# vpac_targetdb register map
Vendor: Texas Instruments
Registers are 32-bit, read-write, no defined reset value unless marked. A register's access mark holds for its fields unless they carry their own. Offsets are as the file gives them; [hi:lo] are bit positions; {n}, {i} and the like mark numbered series; 'fields as' and 'values as' point back to an identical list.

## VPAC (part 4 of 8) — Vision Pre-Processing Accelerator (VPAC)
0x100 GLBCECONFIG — GLBCE Configuration
  [0] GLBCE_PCLKFREE — '1'-> GLBCE pclk is free running , '0' -> GLBCE pclk is gated pixel clock
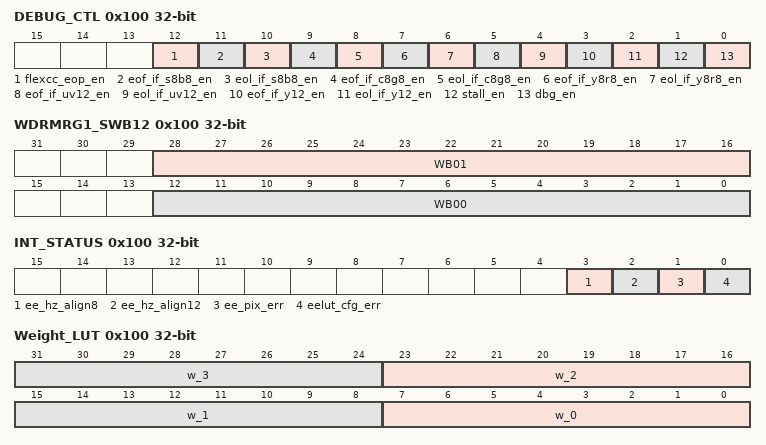
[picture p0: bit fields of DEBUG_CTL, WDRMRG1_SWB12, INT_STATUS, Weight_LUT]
0x100 DEBUG_CTL access per field — Enable for different debug events
  [12] flexcc_eop_en rw — Enable for flexcc eop
  [11] eof_if_s8b8_en rw — Enable for eof on s8b8
  [10] eol_if_s8b8_en rw — Enable for eol on s8b8
  [9] eof_if_c8g8_en rw — Enable for eof on c8g8
  [8] eol_if_c8g8_en rw — Enable for eol on c8g8
  [7] eof_if_y8r8_en rw — Enable for eof on y8r8
  [6] eol_if_y8r8_en rw — Enable for eol on y8r8
  [5] eof_if_uv12_en rw — Enable for eof on uv12
  [4] eol_if_uv12_en rw — Enable for eol on uv12
  [3] eof_if_y12_en rw — Enable for eof on y12
  [2] eol_if_y12_en rw — Enable for eol on y12
  [1] stall_en rw — Enable for stall event
  [0] dbg_en rw — Enable debug features, set to '0' to disable all debug events
0x100 WDRMRG1_SWB12 access per field — First stage WDR merge WB gain 1 and 2 for short frame
  [28:16] WB01 rw — U13Q9, WB gain for short frame at pixel 01
  [12:0] WB00 rw — U13Q9, WB gain for short frame at pixel 00
0x100 INT_STATUS — Status/clear register for flexee interrupts
  [3] ee_hz_align8 — status/clear for EE horizontal aligner yuv8 overflow error indicates that the luma and chroma line starts were not within hardware synchronization limits. Write 1 to clear, write 0 has no effect.
  [2] ee_hz_align12 — status/clear for EE horizontal aligner yuv12 overflow error indicates that the luma and chroma line starts were not within hardware synchronization limits. Write 1 to clear, write 0 has no effect.
  [1] ee_pix_err — status/clear for error on line array, set when software accesses EE pixel array during active frame causing potential frame corruption. Write 1 to clear, write 0 has no effect.
  [0] eelut_cfg_err — status/clear for error on EE LUT cfg, set when software accesses EE LUT during active frame causing potential frame corruption. Write 1 to clear, write 0 has no effect.
0x100 Weight_LUT — This contains weights for LUT. These acts as 1280 size LUT (8 bit each) in Bi-lateral mode, while 24 size (9 bit in 16 bit container) in Generic Filtering mode
  [8n+7:8n] w_{n} (n=0..3) — weight W_{n}
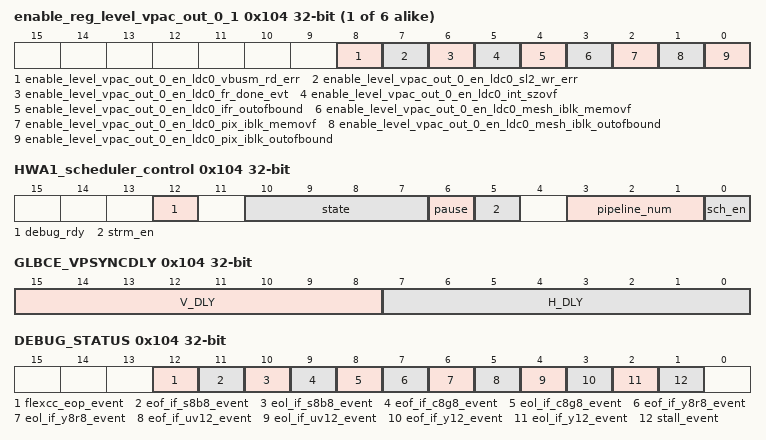
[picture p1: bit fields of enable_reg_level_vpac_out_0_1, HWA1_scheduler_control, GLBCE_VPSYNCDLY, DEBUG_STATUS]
{0x104+0x20*i} enable_reg_level_vpac_out_{i}_1 (i=0..5) — Enable Register {8i+1}
  [8] enable_level_vpac_out_{i}_en_ldc0_vbusm_rd_err — Enable Set for level_vpac_out_{i}_en_ldc0_vbusm_rd_err
  [7] enable_level_vpac_out_{i}_en_ldc0_sl2_wr_err — Enable Set for level_vpac_out_{i}_en_ldc0_sl2_wr_err
  [6] enable_level_vpac_out_{i}_en_ldc0_fr_done_evt — Enable Set for level_vpac_out_{i}_en_ldc0_fr_done_evt
  [5] enable_level_vpac_out_{i}_en_ldc0_int_szovf — Enable Set for level_vpac_out_{i}_en_ldc0_int_szovf
  [4] enable_level_vpac_out_{i}_en_ldc0_ifr_outofbound — Enable Set for level_vpac_out_{i}_en_ldc0_ifr_outofbound
  [3] enable_level_vpac_out_{i}_en_ldc0_mesh_iblk_memovf — Enable Set for level_vpac_out_{i}_en_ldc0_mesh_iblk_memovf
  [2] enable_level_vpac_out_{i}_en_ldc0_pix_iblk_memovf — Enable Set for level_vpac_out_{i}_en_ldc0_pix_iblk_memovf
  [1] enable_level_vpac_out_{i}_en_ldc0_mesh_iblk_outofbound — Enable Set for level_vpac_out_{i}_en_ldc0_mesh_iblk_outofbound
  [0] enable_level_vpac_out_{i}_en_ldc0_pix_iblk_outofbound — Enable Set for level_vpac_out_{i}_en_ldc0_pix_iblk_outofbound
0x104 HWA1_scheduler_control access per field — Scheduler Control Register
  [12] debug_rdy rw — '0' -> HWA1 Scheduler resources must not be read during halted state. '1'-> HWA1 Scheduler resources are readable during halted state
  [10:7] state ro — Current state of HWA1 Scheduler
  [6] pause rw — '1' -> pause/suspend scheduler , '0' -> resume scheduler
  [5] strm_en rw — '1' -> Streaming input enable, '0' No streaming input
  [3:1] pipeline_num rw — Pipeline Number of HWA1 Scheduler
  [0] sch_en rw — scheduler enable; write '1' to enable scheduler
0x104 GLBCE_VPSYNCDLY — Delay of GLBCE Core, used to regenerate VS/VE VPORT signals
  [15:8] V_DLY — Line delay between GLBCE.VS_In to GLBCE.VS_Out
  [7:0] H_DLY — Cycle delay between GLBCE.HS_In to GLBCE.HS_Out minus 1
0x104 DEBUG_STATUS access per field — Set/Clear for debug events
  [12] flexcc_eop_event rw — Status/Clear for flexcc eop, write '1' to clear
  [11] eof_if_s8b8_event rw — Status/Clear for eof on s8b8, write '1' to clear
  [10] eol_if_s8b8_event rw — Status/Clear for eol on s8b8, write '1' to clear
  [9] eof_if_c8g8_event rw — Status/Clear for eof on c8g8, write '1' to clear
  [8] eol_if_c8g8_event rw — Status/Clear for eol on c8g8, write '1' to clear
  [7] eof_if_y8r8_event rw — Status/Clear for eof on y8r8, write '1' to clear
  [6] eol_if_y8r8_event rw — Status/Clear for eol on y8r8, write '1' to clear
  [5] eof_if_uv12_event rw — Status/Clear for eof on uv12, write '1' to clear
  [4] eol_if_uv12_event rw — Status/Clear for eol on uv12, write '1' to clear
  [3] eof_if_y12_event rw — Status/Clear for eof on y12, write '1' to clear
  [2] eol_if_y12_event rw — Status/Clear for eol on y12, write '1' to clear
  [1] stall_event rw — Status/Clear for stall event, write '1' to clear
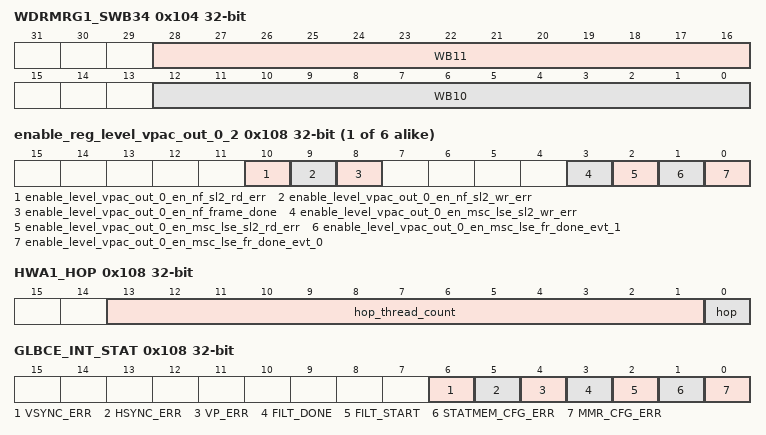
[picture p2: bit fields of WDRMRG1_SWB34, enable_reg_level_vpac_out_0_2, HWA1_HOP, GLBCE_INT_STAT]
0x104 WDRMRG1_SWB34 access per field — First stage WDR merge WB gain 3 and 4 for short frame
  [28:16] WB11 rw — U13Q9, WB gain for short frame at pixel 11
  [12:0] WB10 rw — U13Q9, WB gain for short frame at pixel 10
{0x108+0x20*i} enable_reg_level_vpac_out_{i}_2 (i=0..5) — Enable Register {8i+2}
  [10] enable_level_vpac_out_{i}_en_nf_sl2_rd_err — Enable Set for level_vpac_out_{i}_en_nf_sl2_rd_err
  [9] enable_level_vpac_out_{i}_en_nf_sl2_wr_err — Enable Set for level_vpac_out_{i}_en_nf_sl2_wr_err
  [8] enable_level_vpac_out_{i}_en_nf_frame_done — Enable Set for level_vpac_out_{i}_en_nf_frame_done
  [3] enable_level_vpac_out_{i}_en_msc_lse_sl2_wr_err — Enable Set for level_vpac_out_{i}_en_msc_lse_sl2_wr_err
  [2] enable_level_vpac_out_{i}_en_msc_lse_sl2_rd_err — Enable Set for level_vpac_out_{i}_en_msc_lse_sl2_rd_err
  [1] enable_level_vpac_out_{i}_en_msc_lse_fr_done_evt_1 — Enable Set for level_vpac_out_{i}_en_msc_lse_fr_done_evt_1
  [0] enable_level_vpac_out_{i}_en_msc_lse_fr_done_evt_0 — Enable Set for level_vpac_out_{i}_en_msc_lse_fr_done_evt_0
0x108 HWA1_HOP — Scheduler HOP Control Register. Help in detecting eop within scheduler. Once configured, it counts task/channel starts and stops issuing further start. Specifically useful for Head of pipe dma scheduler .
  [13:1] hop_thread_count — Number of Task count for Head of pipe
  [0] hop — '1' -> Head of Pipe producer Sch , '0' -> No hop
0x108 GLBCE_INT_STAT — Set on internal interutp event and clr by SW
  [6] VSYNC_ERR — status/clear for GLBCE VSYNC Delay programmation error. Set Delayed sync signals doesn't match with sync signal generated from GLBCE Core
  [5] HSYNC_ERR — status/clear for GLBCE HSYNC Delay programmation error. Set Delayed sync signals doesn't match with sync signal generated from GLBCE Core
  [4] VP_ERR — status/clear for GLBCE Input frame start error. Set Input frame is started while filtering is going on
  [3] FILT_DONE — status/clear for GLBCE Filtering Done event. Set when GLBCE Filtering is completed.
  [2] FILT_START — status/clear for GLBCE Filtering Start event. Set when GLBCE Filtering starts
  [1] STATMEM_CFG_ERR — status/clear for statastics memory configuration error. Set when access happen to statastics memory in the middle of processing
  [0] MMR_CFG_ERR — status/clear for mmr configuration error. Set when writes happen to non-shadowed registers in the middle of processing
0x108 DEBUG_RAW — Set/Clear for debug RAW mode
  [0] dbg_raw_mode — Enable debug RAW mode, takes input from RAWFE and delivers to FlexCC as C1={raw[11:0]}, C2={4'd0,raw[7:0]}, C3={4'd0,raw[15:8]}, c4={8'd0,raw[15:12]}
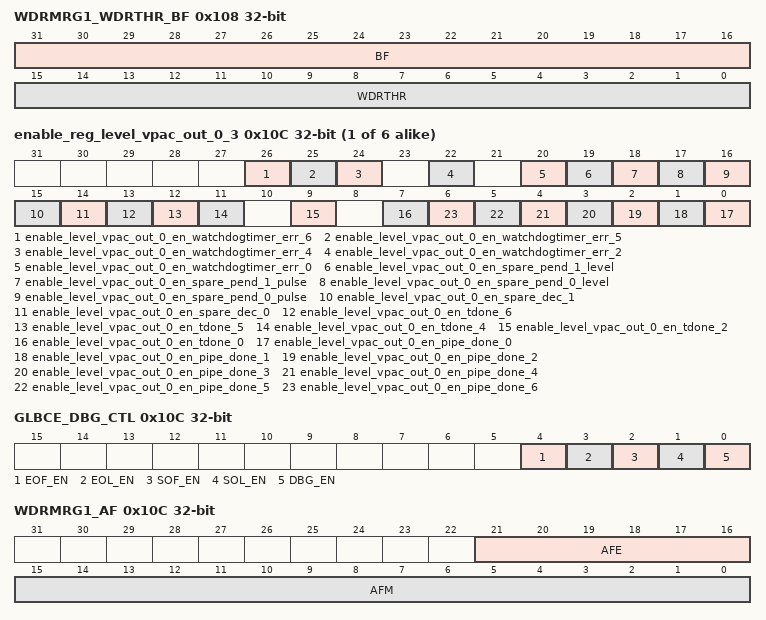
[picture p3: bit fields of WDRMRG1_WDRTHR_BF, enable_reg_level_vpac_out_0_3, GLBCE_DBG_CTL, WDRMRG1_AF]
0x108 WDRMRG1_WDRTHR_BF — First stage WDR merge parameter WDRTHR and BF
  [31:16] BF — S16, bf parameter for merge
  [15:0] WDRTHR — U16, WDR threshold for merge
{0x10C+0x20*i} enable_reg_level_vpac_out_{i}_3 (i=0..5) — Enable Register {8i+3}
  [26] enable_level_vpac_out_{i}_en_watchdogtimer_err_6 — Enable Set for level_vpac_out_{i}_en_watchdogtimer_err_6
  [25] enable_level_vpac_out_{i}_en_watchdogtimer_err_5 — Enable Set for level_vpac_out_{i}_en_watchdogtimer_err_5
  [24] enable_level_vpac_out_{i}_en_watchdogtimer_err_4 — Enable Set for level_vpac_out_{i}_en_watchdogtimer_err_4
  [22] enable_level_vpac_out_{i}_en_watchdogtimer_err_2 — Enable Set for level_vpac_out_{i}_en_watchdogtimer_err_2
  [20] enable_level_vpac_out_{i}_en_watchdogtimer_err_0 — Enable Set for level_vpac_out_{i}_en_watchdogtimer_err_0
  [19] enable_level_vpac_out_{i}_en_spare_pend_1_level — Enable Set for level_vpac_out_{i}_en_spare_pend_1_level
  [18] enable_level_vpac_out_{i}_en_spare_pend_1_pulse — Enable Set for level_vpac_out_{i}_en_spare_pend_1_pulse
  [17] enable_level_vpac_out_{i}_en_spare_pend_0_level — Enable Set for level_vpac_out_{i}_en_spare_pend_0_level
  [16] enable_level_vpac_out_{i}_en_spare_pend_0_pulse — Enable Set for level_vpac_out_{i}_en_spare_pend_0_pulse
  [15] enable_level_vpac_out_{i}_en_spare_dec_1 — Enable Set for level_vpac_out_{i}_en_spare_dec_1
  [14] enable_level_vpac_out_{i}_en_spare_dec_0 — Enable Set for level_vpac_out_{i}_en_spare_dec_0
  [13] enable_level_vpac_out_{i}_en_tdone_6 — Enable Set for level_vpac_out_{i}_en_tdone_6
  [12] enable_level_vpac_out_{i}_en_tdone_5 — Enable Set for level_vpac_out_{i}_en_tdone_5
  [11] enable_level_vpac_out_{i}_en_tdone_4 — Enable Set for level_vpac_out_{i}_en_tdone_4
  [9] enable_level_vpac_out_{i}_en_tdone_2 — Enable Set for level_vpac_out_{i}_en_tdone_2
  [7] enable_level_vpac_out_{i}_en_tdone_0 — Enable Set for level_vpac_out_{i}_en_tdone_0
  [n] enable_level_vpac_out_{i}_en_pipe_done_{n} (n=0..6) — Enable Set for level_vpac_out_{i}_en_pipe_done_{n}
0x10C GLBCE_DBG_CTL — Enable for GLBCE debug events
  [4] EOF_EN — Enable for EOF at GLBCE output
  [3] EOL_EN — Enable for EOF at GLBCE output
  [2] SOF_EN — Enable for SOF at GLBCE input
  [1] SOL_EN — Enable for SOL at GLBCE input
  [0] DBG_EN — Enable debug features, set to '0' to disable all debug events
0x10C WDRMRG1_AF access per field — First stage WDR merge parameter AF
  [21:16] AFE rw — U6, af_e parameter for merge
  [15:0] AFM rw — S16, af_m parameter for merge
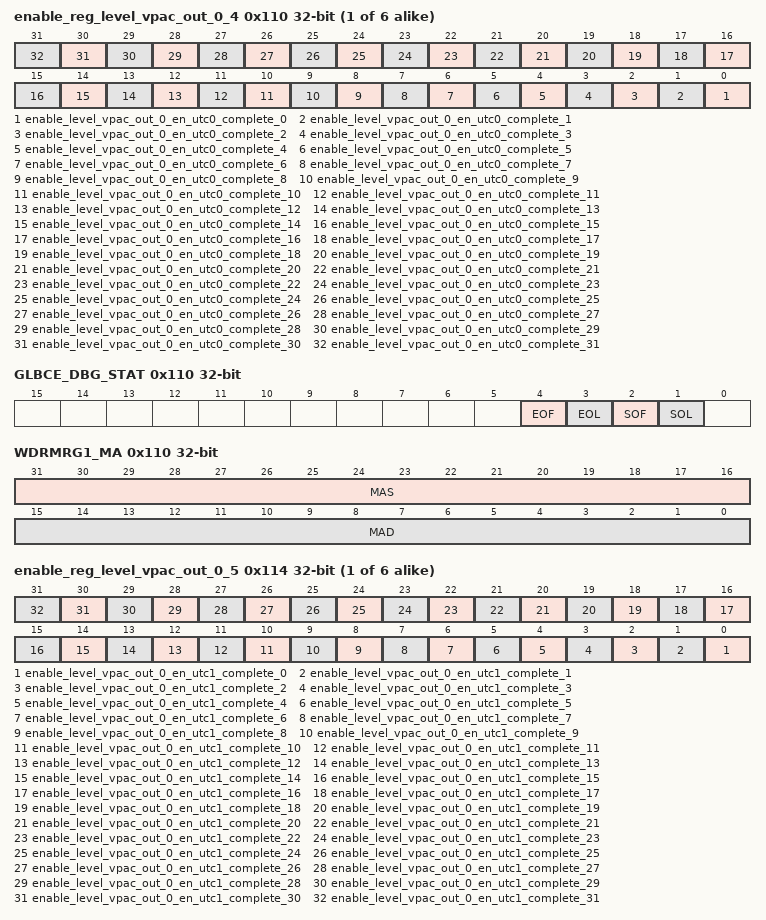
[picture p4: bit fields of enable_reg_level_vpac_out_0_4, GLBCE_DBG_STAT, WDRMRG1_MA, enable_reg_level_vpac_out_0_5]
{0x110+0x20*i} enable_reg_level_vpac_out_{i}_4 (i=0..5) — Enable Register {8i+4}
  [n] enable_level_vpac_out_{i}_en_utc0_complete_{n} (n=0..31) — Enable Set for level_vpac_out_{i}_en_utc0_complete_{n}
0x110 GLBCE_DBG_STAT — Set/Clear for GLBCE debug events
  [4] EOF — Status/Clear for EOF at GLBCE output. Set on EOF at GLBCE output
  [3] EOL — Status/Clear for EOF at GLBCE output. Set on EOL at GLBCE output
  [2] SOF — Status/Clear for SOF at GLBCE input. Set on SOF at GLBCE input
  [1] SOL — Status/Clear for SOL at GLBCE input. Set on SOL at GLBCE input
0x110 WDRMRG1_MA — First stage WDR merge parameter MA
  [31:16] MAS — U16, slope for merge MA filter
  [15:0] MAD — U16, lower threshold for merge MA filter
{0x114+0x20*i} enable_reg_level_vpac_out_{i}_5 (i=0..5) — Enable Register {8i+5}
  [n] enable_level_vpac_out_{i}_en_utc1_complete_{n} (n=0..31) — Enable Set for level_vpac_out_{i}_en_utc1_complete_{n}
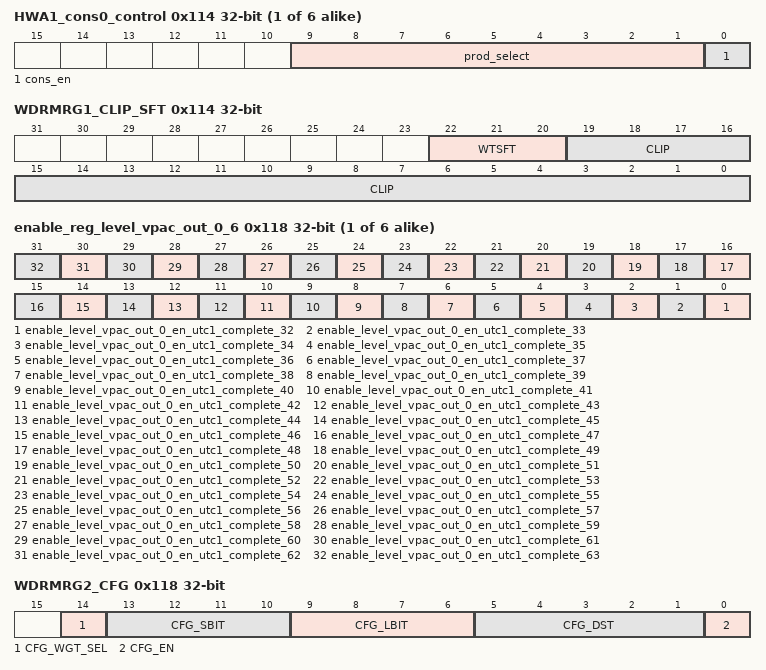
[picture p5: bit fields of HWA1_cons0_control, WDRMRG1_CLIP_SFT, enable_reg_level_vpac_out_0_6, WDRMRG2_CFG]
{0x114+4i} HWA1_cons{i}_control (i=0..5) — Controlling consumer socket {i} for HWA1
  [9:1] prod_select — producer select for HWA1 cons socket {i}
  [0] cons_en — '1' -> Consumer socket {i} enable , '0' Disable
0x114 WDRMRG1_CLIP_SFT access per field — First stage WDR merge clip value and shift before weight block
  [22:20] WTSFT rw — U3, shift before weight block
  [19:0] CLIP rw — U20, output clip value. It is a software restriction to always ensure that the clipped value is a 16-bit number for first wdr stage.
{0x118+0x20*i} enable_reg_level_vpac_out_{i}_6 (i=0..5) — Enable Register {8i+6}
  [n-32] enable_level_vpac_out_{i}_en_utc1_complete_{n} (n=32..63) — Enable Set for level_vpac_out_{i}_en_utc1_complete_{n}
0x118 WDRMRG2_CFG access per field — Second stage WDR merge configuration
  [14] CFG_WGT_SEL rw — Select source for weight calculation (0:long, 1: short)
  [13:10] CFG_SBIT rw — U4, short exposure image bit shift
  [9:6] CFG_LBIT rw — U4, long exposure image bit shift
  [5:1] CFG_DST rw — U5, down shift value after WDR merge
  [0] CFG_EN rw — enable
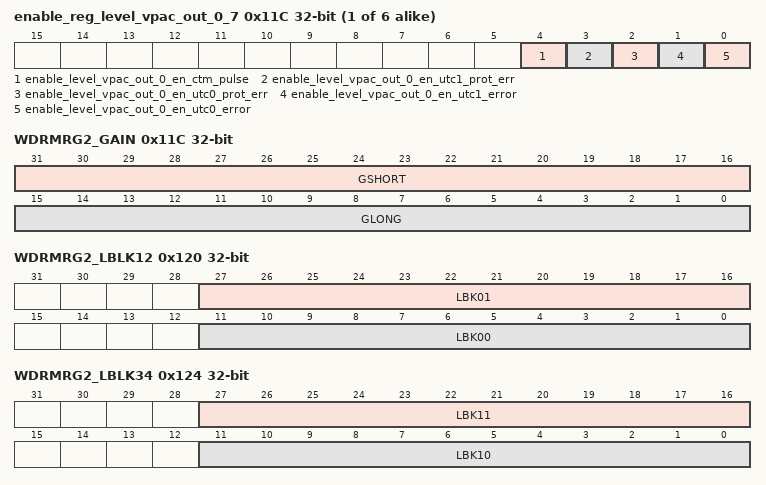
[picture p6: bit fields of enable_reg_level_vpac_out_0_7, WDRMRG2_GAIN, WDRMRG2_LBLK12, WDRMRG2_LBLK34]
{0x11C+0x20*i} enable_reg_level_vpac_out_{i}_7 (i=0..5) — Enable Register {8i+7}
  [4] enable_level_vpac_out_{i}_en_ctm_pulse — Enable Set for level_vpac_out_{i}_en_ctm_pulse
  [3] enable_level_vpac_out_{i}_en_utc1_prot_err — Enable Set for level_vpac_out_{i}_en_utc1_prot_err
  [2] enable_level_vpac_out_{i}_en_utc0_prot_err — Enable Set for level_vpac_out_{i}_en_utc0_prot_err
  [1] enable_level_vpac_out_{i}_en_utc1_error — Enable Set for level_vpac_out_{i}_en_utc1_error
  [0] enable_level_vpac_out_{i}_en_utc0_error — Enable Set for level_vpac_out_{i}_en_utc0_error
0x11C WDRMRG2_GAIN — Second stage WDR merge gain
  [31:16] GSHORT — U16Q15, gain for long frame
  [15:0] GLONG — U16Q15, gain for short frame
0x120 WDRMRG2_LBLK12 access per field — Second stage WDR merge black level 1 and 2 for long frame
  [27:16] LBK01 rw — U12, black level for long frame at pixel 01
  [11:0] LBK00 rw — U12, black level for long frame at pixel 00
0x124 WDRMRG2_LBLK34 access per field — Second stage WDR merge black level 3 and 4 for long frame
  [27:16] LBK11 rw — U12, black level for long frame at pixel 11
  [11:0] LBK10 rw — U12, black level for long frame at pixel 10
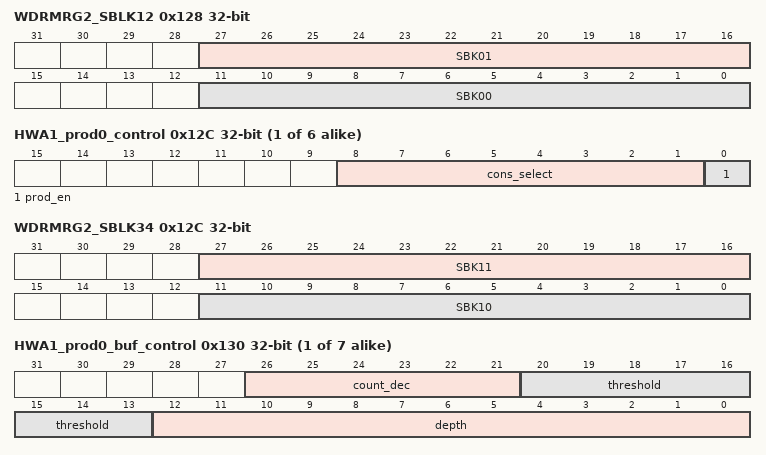
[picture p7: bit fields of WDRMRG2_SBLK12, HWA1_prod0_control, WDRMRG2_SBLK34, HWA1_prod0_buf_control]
0x128 WDRMRG2_SBLK12 access per field — Second stage WDR merge black level 1 and 2 for short frame
  [27:16] SBK01 rw — U12, black level for short frame at pixel 01
  [11:0] SBK00 rw — U12, black level for short frame at pixel 00
{0x12C+0x14*i} HWA1_prod{i}_control (i=0..5) — Controlling producer socket{i} for HWA1
  [8:1] cons_select — consumer select for HWA1 prod socket {i}. Used in decrementing count of producer buffer
  [0] prod_en — '1' -> Producer socket 0 enable , '0' Disable
0x12C WDRMRG2_SBLK34 access per field — Second stage WDR merge black level 3 and 4 for short frame
  [27:16] SBK11 rw — U12, black level for short frame at pixel 11
  [11:0] SBK10 rw — U12, black level for short frame at pixel 10
{0x130+0x14*i} HWA1_prod{i}_buf_control (i=0..6) — Controlling producer socket{i} buffer for HWA1
  [26:21] count_dec — Count decrement value for prod count
  [20:13] threshold — Count threshold to generate pend for consumer
  [12:0] depth — Maximum number of producer buffer count
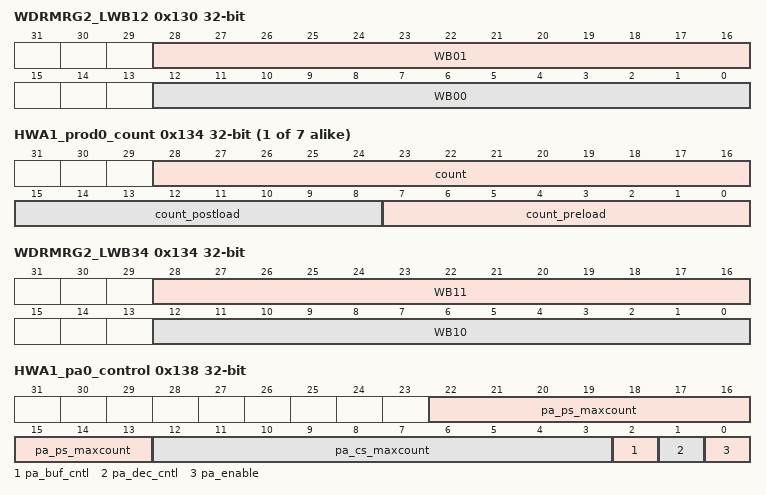
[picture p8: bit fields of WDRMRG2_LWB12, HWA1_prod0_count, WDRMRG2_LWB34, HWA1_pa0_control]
0x130 WDRMRG2_LWB12 access per field — Second stage WDR merge WB gain 1 and 2 for long frame
  [28:16] WB01 rw — U13Q9, WB gain for long frame at pixel 01
  [12:0] WB00 rw — U13Q9, WB gain for long frame at pixel 00
{0x134+0x14*i} HWA1_prod{i}_count access per field (i=0..6) — Defining count values for pre/post load for generating pend by HWA1 prod{i}
  [28:16] count ro — current count value
  [15:8] count_postload rw — count postload after producer max thread count reached
  [7:0] count_preload rw — count preload after scheduler start/init
0x134 WDRMRG2_LWB34 access per field — Second stage WDR merge WB gain 3 and 4 for long frame
  [28:16] WB11 rw — U13Q9, WB gain for long frame at pixel 11
  [12:0] WB10 rw — U13Q9, WB gain for long frame at pixel 10
0x138 HWA1_pa0_control — control register to manage pattern adapter on HWA1 prod socket0
  [22:13] pa_ps_maxcount — destination count for pattern adaptation (N), M --> N
  [12:3] pa_cs_maxcount — source count for pattern adaptation (M), M --> N
  [2] pa_buf_cntl — '1' -> Apply threshold, count_preload and count_postload on pattern adapter count (use this only when pa_enable='1') '0' -> Apply threshold, count_preload and count_postload on prod count (same behavior as if no pattern adapter. Note when pa_enable='1' and pa_buf_cntl='0' threshold is not used and ignored)
  [1] pa_dec_cntl — '1' -> post pattern adaptation, decrement ps count by count_dec , '0' -> post pattern adaptation, decrement ps count by pa_cs_maxcount
  [0] pa_enable — '1' -> pa enable, '0' -> disable
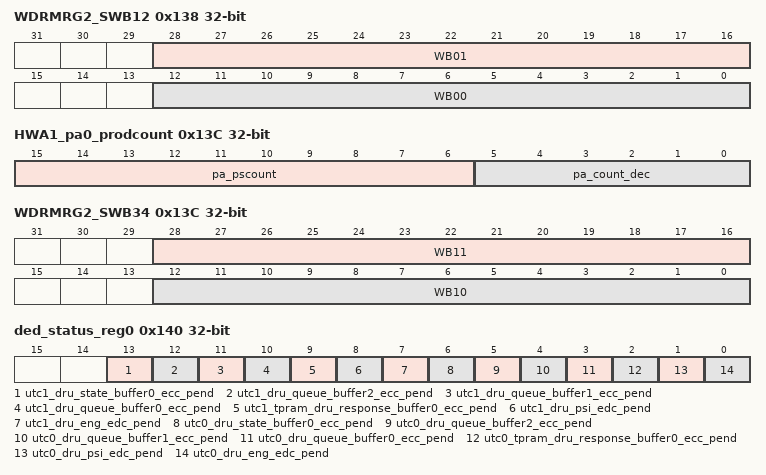
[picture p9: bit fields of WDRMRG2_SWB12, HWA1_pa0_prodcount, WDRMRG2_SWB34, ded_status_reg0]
0x138 WDRMRG2_SWB12 access per field — Second stage WDR merge WB gain 1 and 2 for short frame
  fields as WDRMRG1_SWB12
0x13C HWA1_pa0_prodcount access per field — count values for HWA1 prod socket0
  [15:6] pa_pscount ro — current count value of pa prod count
  [5:0] pa_count_dec rw — Decrement count value of pa_prod_count after pattern adapter prod count reaches threshold
0x13C ded_eoi_reg — EOI Register
  [0] eoi_wr
0x13C ded_eoi_reg — EOI Register
  [0] eoi_wr
0x13C ded_eoi_reg — EOI Register
  [0] eoi_wr
0x13C WDRMRG2_SWB34 access per field — Second stage WDR merge WB gain 3 and 4 for short frame
  fields as WDRMRG1_SWB34
0x140 ded_status_reg0 — Interrupt Status Register 0
  [13] utc1_dru_state_buffer0_ecc_pend — Interrupt Pending Status for utc1_dru_state_buffer0_ecc_pend
  [12] utc1_dru_queue_buffer2_ecc_pend — Interrupt Pending Status for utc1_dru_queue_buffer2_ecc_pend
  [11] utc1_dru_queue_buffer1_ecc_pend — Interrupt Pending Status for utc1_dru_queue_buffer1_ecc_pend
  [10] utc1_dru_queue_buffer0_ecc_pend — Interrupt Pending Status for utc1_dru_queue_buffer0_ecc_pend
  [9] utc1_tpram_dru_response_buffer0_ecc_pend — Interrupt Pending Status for utc1_tpram_dru_response_buffer0_ecc_pend
  [8] utc1_dru_psi_edc_pend — Interrupt Pending Status for utc1_dru_psi_edc_pend
  [7] utc1_dru_eng_edc_pend — Interrupt Pending Status for utc1_dru_eng_edc_pend
  [6] utc0_dru_state_buffer0_ecc_pend — Interrupt Pending Status for utc0_dru_state_buffer0_ecc_pend
  [5] utc0_dru_queue_buffer2_ecc_pend — Interrupt Pending Status for utc0_dru_queue_buffer2_ecc_pend
  [4] utc0_dru_queue_buffer1_ecc_pend — Interrupt Pending Status for utc0_dru_queue_buffer1_ecc_pend
  [3] utc0_dru_queue_buffer0_ecc_pend — Interrupt Pending Status for utc0_dru_queue_buffer0_ecc_pend
  [2] utc0_tpram_dru_response_buffer0_ecc_pend — Interrupt Pending Status for utc0_tpram_dru_response_buffer0_ecc_pend
  [1] utc0_dru_psi_edc_pend — Interrupt Pending Status for utc0_dru_psi_edc_pend
  [0] utc0_dru_eng_edc_pend — Interrupt Pending Status for utc0_dru_eng_edc_pend
0x140 ded_status_reg0 — Interrupt Status Register 0
  [n+8] meshmem_b{n}_p1_ramecc_pend (n=0..3) — Interrupt Pending Status for meshmem_b{n}_p1_ramecc_pend
  [n+4] meshmem_b{n}_p0_ramecc_pend (n=0..3) — Interrupt Pending Status for meshmem_b{n}_p0_ramecc_pend
  [3] dualc_lut_b1_ramecc_pend — Interrupt Pending Status for dualc_lut_b1_ramecc_pend
  [2] dualc_lut_b0_ramecc_pend — Interrupt Pending Status for dualc_lut_b0_ramecc_pend
  [1] dualy_lut_b1_ramecc_pend — Interrupt Pending Status for dualy_lut_b1_ramecc_pend
  [0] dualy_lut_b0_ramecc_pend — Interrupt Pending Status for dualy_lut_b0_ramecc_pend
0x140 psa_signature ro — The PSA_SIGNATURE register returns the captured PSA signature value of the last frame data of output channel [a].
  [31:0] value — 32-bit CRC signature value
0x140 ded_status_reg0 — Interrupt Status Register 0
  [31] fcc_lut1_ram1_ramecc_pend — Interrupt Pending Status for fcc_lut1_ram1_ramecc_pend
  [30] fcc_lut1_ram0_ramecc_pend — Interrupt Pending Status for fcc_lut1_ram0_ramecc_pend
  [29] fcc_lut0_ram1_ramecc_pend — Interrupt Pending Status for fcc_lut0_ram1_ramecc_pend
  [28] fcc_lut0_ram0_ramecc_pend — Interrupt Pending Status for fcc_lut0_ram0_ramecc_pend
  [27] fcc_cont_lut3_ram1_ramecc_pend — Interrupt Pending Status for fcc_cont_lut3_ram1_ramecc_pend
  [26] fcc_cont_lut3_ram0_ramecc_pend — Interrupt Pending Status for fcc_cont_lut3_ram0_ramecc_pend
  [25] fcc_cont_lut2_ram1_ramecc_pend — Interrupt Pending Status for fcc_cont_lut2_ram1_ramecc_pend
  [24] fcc_cont_lut2_ram0_ramecc_pend — Interrupt Pending Status for fcc_cont_lut2_ram0_ramecc_pend
  [23] fcc_cont_lut1_ram1_ramecc_pend — Interrupt Pending Status for fcc_cont_lut1_ram1_ramecc_pend
  [22] fcc_cont_lut1_ram0_ramecc_pend — Interrupt Pending Status for fcc_cont_lut1_ram0_ramecc_pend
  [21] fcc_hist_ram1_ramecc_pend — Interrupt Pending Status for fcc_hist_ram1_ramecc_pend
  [20] fcc_hist_ram0_ramecc_pend — Interrupt Pending Status for fcc_hist_ram0_ramecc_pend
  [n+12] stat_mem{n}_ramecc_pend (n=0..7) — Interrupt Pending Status for stat_mem{n}_ramecc_pend
  [11] h3a_lut_ram1_ramecc_pend — Interrupt Pending Status for h3a_lut_ram1_ramecc_pend
  [10] h3a_lut_ram0_ramecc_pend — Interrupt Pending Status for h3a_lut_ram0_ramecc_pend
  [9] lsc_ramecc_pend — Interrupt Pending Status for lsc_ramecc_pend
  [8] dpc_lut_ramecc_pend — Interrupt Pending Status for dpc_lut_ramecc_pend
  [7] wdr_lut_ram1_ramecc_pend — Interrupt Pending Status for wdr_lut_ram1_ramecc_pend
  [6] wdr_lut_ram0_ramecc_pend — Interrupt Pending Status for wdr_lut_ram0_ramecc_pend
  [5] lut1_ram1_ramecc_pend — Interrupt Pending Status for lut1_ram1_ramecc_pend
  [4] lut1_ram0_ramecc_pend — Interrupt Pending Status for lut1_ram0_ramecc_pend
  [3] lut2_ram1_ramecc_pend — Interrupt Pending Status for lut2_ram1_ramecc_pend
  [2] lut2_ram0_ramecc_pend — Interrupt Pending Status for lut2_ram0_ramecc_pend
  [1] lut3_ram1_ramecc_pend — Interrupt Pending Status for lut3_ram1_ramecc_pend
  [0] lut3_ram0_ramecc_pend — Interrupt Pending Status for lut3_ram0_ramecc_pend
0x140 psa_signature ro — The PSA_SIGNATURE register returns the captured PSA signature value of the last frame data of output channel [a].
  [31:0] value — 32-bit CRC signature value
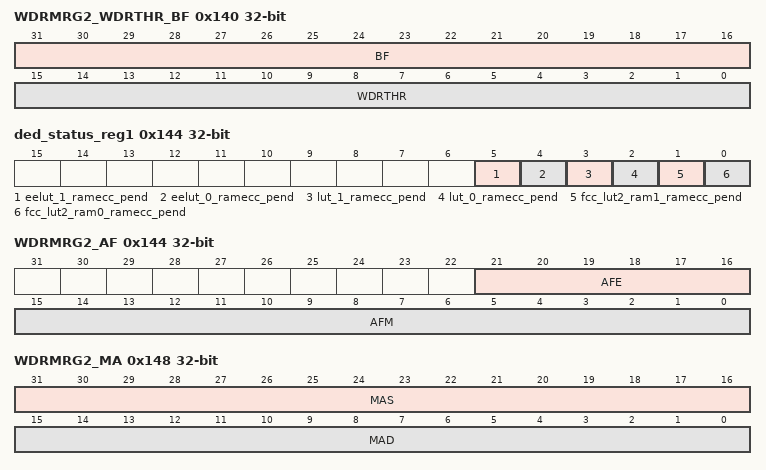
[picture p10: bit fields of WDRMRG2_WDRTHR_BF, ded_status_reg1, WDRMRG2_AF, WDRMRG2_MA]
0x140 WDRMRG2_WDRTHR_BF — Second stage WDR merge parameter WDRTHR and BF
  fields as WDRMRG1_WDRTHR_BF
0x140 psa_signature ro — The PSA_SIGNATURE register returns the captured PSA signature value of the last frame data of output channel [a].
  [31:0] value — 32-bit CRC signature value
0x140 psa_signature ro — The PSA_SIGNATURE register returns the captured PSA signature value of the last frame data of output channel [a].
  [31:0] value — 32-bit CRC signature value
0x144 ded_status_reg1 — Interrupt Status Register 1
  [5] eelut_1_ramecc_pend — Interrupt Pending Status for eelut_1_ramecc_pend
  [4] eelut_0_ramecc_pend — Interrupt Pending Status for eelut_0_ramecc_pend
  [3] lut_1_ramecc_pend — Interrupt Pending Status for lut_1_ramecc_pend
  [2] lut_0_ramecc_pend — Interrupt Pending Status for lut_0_ramecc_pend
  [1] fcc_lut2_ram1_ramecc_pend — Interrupt Pending Status for fcc_lut2_ram1_ramecc_pend
  [0] fcc_lut2_ram0_ramecc_pend — Interrupt Pending Status for fcc_lut2_ram0_ramecc_pend
0x144 WDRMRG2_AF access per field — Second stage WDR merge parameter AF
  fields as WDRMRG1_AF
0x148 WDRMRG2_MA — Second stage WDR merge parameter MA
  fields as WDRMRG1_MA
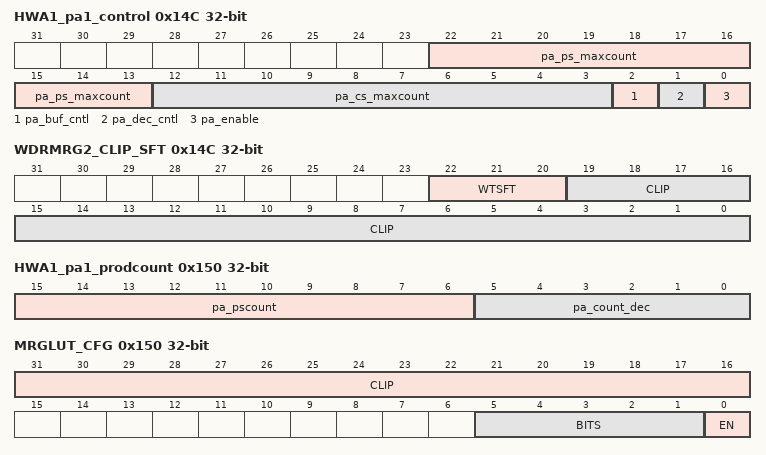
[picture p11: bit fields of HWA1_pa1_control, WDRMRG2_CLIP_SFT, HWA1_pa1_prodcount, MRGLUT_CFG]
0x14C HWA1_pa1_control — control register to manage pattern adapter on HWA1 prod socket1
  fields as HWA1_pa0_control
0x14C WDRMRG2_CLIP_SFT access per field — Second stage WDR merge clip value and shift before weight block
  [22:20] WTSFT rw — U3, shift before weight block
  [19:0] CLIP rw — U20, output clip value
0x150 HWA1_pa1_prodcount access per field — count values for HWA1 prod socket1
  fields as HWA1_pa0_prodcount
0x150 MRGLUT_CFG access per field — Merge LUT configuration
  [31:16] CLIP rw — U16, LUT output clip
  [5:1] BITS rw — U5, LUT input bit depth, up to 24
  [0] EN rw — LUT enable
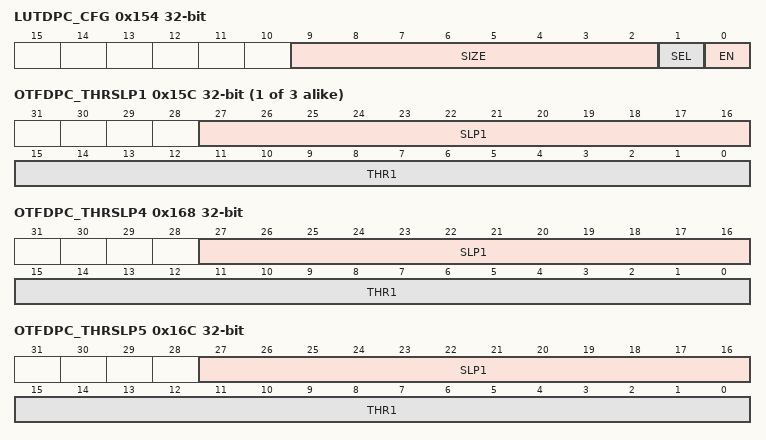
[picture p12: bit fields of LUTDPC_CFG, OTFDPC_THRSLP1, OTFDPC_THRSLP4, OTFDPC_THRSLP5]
0x154 LUTDPC_CFG access per field — LUTDPC configuration
  [9:2] SIZE rw — U8, number of LUT entires - 1
  [1] SEL rw — replace with black (0) or whithe (1)
  [0] EN rw — LUTDPC enable
0x158 OTFDPC_EN access per field — OTFDPC enable
  [0] EN rw — OTF DPC enable
{0x158+4i} OTFDPC_THRSLP{i} access per field (i=1..3) — OTFDPC threshold and slope {i}
  [27:16] SLP1 rw — S12Q8, slope at {512i-512}
  [15:0] THR1 rw — U16, threshold at {512i-512}
0x168 OTFDPC_THRSLP4 access per field — OTFDPC threshold and slope 4
  [27:16] SLP1 rw — S12Q8, slope at 2048
  [15:0] THR1 rw — U16, threshold at 2048
0x16C OTFDPC_THRSLP5 access per field — OTFDPC threshold and slope 5
  [27:16] SLP1 rw — S12Q8, slope at 4096
  [15:0] THR1 rw — U16, threshold at 4096
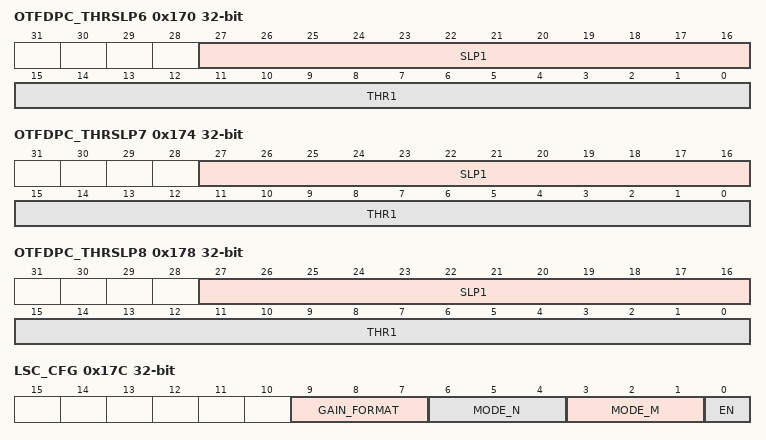
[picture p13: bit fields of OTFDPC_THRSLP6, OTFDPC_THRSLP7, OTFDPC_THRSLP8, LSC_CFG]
0x170 OTFDPC_THRSLP6 access per field — OTFDPC threshold and slope 6
  [27:16] SLP1 rw — S12Q8, slope at 8192
  [15:0] THR1 rw — U16, threshold at 8192
0x174 OTFDPC_THRSLP7 access per field — OTFDPC threshold and slope 7
  [27:16] SLP1 rw — S12Q8, slope at 16384
  [15:0] THR1 rw — U16, threshold at 16384
0x178 OTFDPC_THRSLP8 access per field — OTFDPC threshold and slope 8
  [27:16] SLP1 rw — S12Q8, slope at 32768
  [15:0] THR1 rw — U16, threshold at 32768
0x17C LSC_CFG access per field — LSC configuration
  [9:7] GAIN_FORMAT rw — LSC LUT gain format, 0:Q8, 1:Q8+1, 2:Q7, 3:Q7+1, 4:Q6, 5:Q6+1, 6:Q5, 7:Q5+1
  [6:4] MODE_N rw — vertical LSC LUT downsampling, 3:8x, 4:16x, 5:32x, 6:64x, 7:128x
  [3:1] MODE_M rw — horizontal LSC LUT downsampling, 3:8x, 4:16x, 5:32x, 6:64x, 7:128x
  [0] EN rw — LSC enable
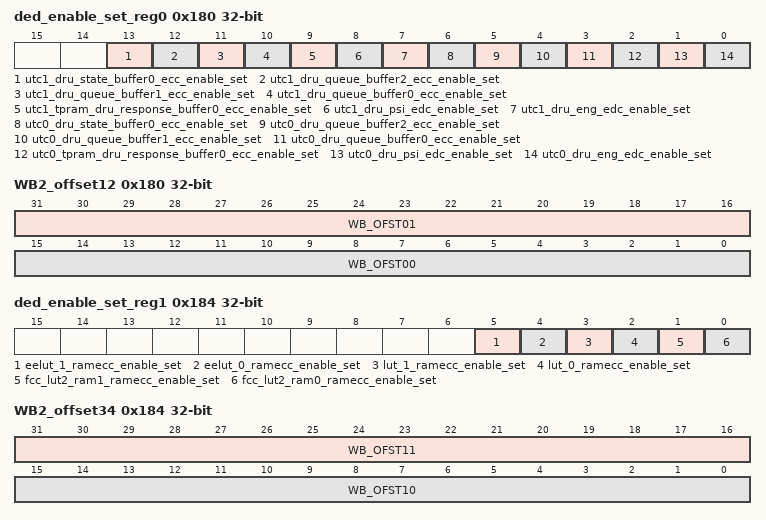
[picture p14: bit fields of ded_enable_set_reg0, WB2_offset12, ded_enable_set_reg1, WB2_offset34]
0x180 ded_enable_set_reg0 — Interrupt Enable Set Register 0
  [13] utc1_dru_state_buffer0_ecc_enable_set — Interrupt Enable Set Register for utc1_dru_state_buffer0_ecc_pend
  [12] utc1_dru_queue_buffer2_ecc_enable_set — Interrupt Enable Set Register for utc1_dru_queue_buffer2_ecc_pend
  [11] utc1_dru_queue_buffer1_ecc_enable_set — Interrupt Enable Set Register for utc1_dru_queue_buffer1_ecc_pend
  [10] utc1_dru_queue_buffer0_ecc_enable_set — Interrupt Enable Set Register for utc1_dru_queue_buffer0_ecc_pend
  [9] utc1_tpram_dru_response_buffer0_ecc_enable_set — Interrupt Enable Set Register for utc1_tpram_dru_response_buffer0_ecc_pend
  [8] utc1_dru_psi_edc_enable_set — Interrupt Enable Set Register for utc1_dru_psi_edc_pend
  [7] utc1_dru_eng_edc_enable_set — Interrupt Enable Set Register for utc1_dru_eng_edc_pend
  [6] utc0_dru_state_buffer0_ecc_enable_set — Interrupt Enable Set Register for utc0_dru_state_buffer0_ecc_pend
  [5] utc0_dru_queue_buffer2_ecc_enable_set — Interrupt Enable Set Register for utc0_dru_queue_buffer2_ecc_pend
  [4] utc0_dru_queue_buffer1_ecc_enable_set — Interrupt Enable Set Register for utc0_dru_queue_buffer1_ecc_pend
  [3] utc0_dru_queue_buffer0_ecc_enable_set — Interrupt Enable Set Register for utc0_dru_queue_buffer0_ecc_pend
  [2] utc0_tpram_dru_response_buffer0_ecc_enable_set — Interrupt Enable Set Register for utc0_tpram_dru_response_buffer0_ecc_pend
  [1] utc0_dru_psi_edc_enable_set — Interrupt Enable Set Register for utc0_dru_psi_edc_pend
  [0] utc0_dru_eng_edc_enable_set — Interrupt Enable Set Register for utc0_dru_eng_edc_pend
0x180 ded_enable_set_reg0 — Interrupt Enable Set Register 0
  [n+8] meshmem_b{n}_p1_ramecc_enable_set (n=0..3) — Interrupt Enable Set Register for meshmem_b{n}_p1_ramecc_pend
  [n+4] meshmem_b{n}_p0_ramecc_enable_set (n=0..3) — Interrupt Enable Set Register for meshmem_b{n}_p0_ramecc_pend
  [3] dualc_lut_b1_ramecc_enable_set — Interrupt Enable Set Register for dualc_lut_b1_ramecc_pend
  [2] dualc_lut_b0_ramecc_enable_set — Interrupt Enable Set Register for dualc_lut_b0_ramecc_pend
  [1] dualy_lut_b1_ramecc_enable_set — Interrupt Enable Set Register for dualy_lut_b1_ramecc_pend
  [0] dualy_lut_b0_ramecc_enable_set — Interrupt Enable Set Register for dualy_lut_b0_ramecc_pend
0x180 ded_enable_set_reg0 — Interrupt Enable Set Register 0
  [31] fcc_lut1_ram1_ramecc_enable_set — Interrupt Enable Set Register for fcc_lut1_ram1_ramecc_pend
  [30] fcc_lut1_ram0_ramecc_enable_set — Interrupt Enable Set Register for fcc_lut1_ram0_ramecc_pend
  [29] fcc_lut0_ram1_ramecc_enable_set — Interrupt Enable Set Register for fcc_lut0_ram1_ramecc_pend
  [28] fcc_lut0_ram0_ramecc_enable_set — Interrupt Enable Set Register for fcc_lut0_ram0_ramecc_pend
  [27] fcc_cont_lut3_ram1_ramecc_enable_set — Interrupt Enable Set Register for fcc_cont_lut3_ram1_ramecc_pend
  [26] fcc_cont_lut3_ram0_ramecc_enable_set — Interrupt Enable Set Register for fcc_cont_lut3_ram0_ramecc_pend
  [25] fcc_cont_lut2_ram1_ramecc_enable_set — Interrupt Enable Set Register for fcc_cont_lut2_ram1_ramecc_pend
  [24] fcc_cont_lut2_ram0_ramecc_enable_set — Interrupt Enable Set Register for fcc_cont_lut2_ram0_ramecc_pend
  [23] fcc_cont_lut1_ram1_ramecc_enable_set — Interrupt Enable Set Register for fcc_cont_lut1_ram1_ramecc_pend
  [22] fcc_cont_lut1_ram0_ramecc_enable_set — Interrupt Enable Set Register for fcc_cont_lut1_ram0_ramecc_pend
  [21] fcc_hist_ram1_ramecc_enable_set — Interrupt Enable Set Register for fcc_hist_ram1_ramecc_pend
  [20] fcc_hist_ram0_ramecc_enable_set — Interrupt Enable Set Register for fcc_hist_ram0_ramecc_pend
  [n+12] stat_mem{n}_ramecc_enable_set (n=0..7) — Interrupt Enable Set Register for stat_mem{n}_ramecc_pend
  [11] h3a_lut_ram1_ramecc_enable_set — Interrupt Enable Set Register for h3a_lut_ram1_ramecc_pend
  [10] h3a_lut_ram0_ramecc_enable_set — Interrupt Enable Set Register for h3a_lut_ram0_ramecc_pend
  [9] lsc_ramecc_enable_set — Interrupt Enable Set Register for lsc_ramecc_pend
  [8] dpc_lut_ramecc_enable_set — Interrupt Enable Set Register for dpc_lut_ramecc_pend
  [7] wdr_lut_ram1_ramecc_enable_set — Interrupt Enable Set Register for wdr_lut_ram1_ramecc_pend
  [6] wdr_lut_ram0_ramecc_enable_set — Interrupt Enable Set Register for wdr_lut_ram0_ramecc_pend
  [5] lut1_ram1_ramecc_enable_set — Interrupt Enable Set Register for lut1_ram1_ramecc_pend
  [4] lut1_ram0_ramecc_enable_set — Interrupt Enable Set Register for lut1_ram0_ramecc_pend
  [3] lut2_ram1_ramecc_enable_set — Interrupt Enable Set Register for lut2_ram1_ramecc_pend
  [2] lut2_ram0_ramecc_enable_set — Interrupt Enable Set Register for lut2_ram0_ramecc_pend
  [1] lut3_ram1_ramecc_enable_set — Interrupt Enable Set Register for lut3_ram1_ramecc_pend
  [0] lut3_ram0_ramecc_enable_set — Interrupt Enable Set Register for lut3_ram0_ramecc_pend
0x180 WB2_offset12 — WB2 white balance offset 1 and 2
  [31:16] WB_OFST01 — S16, WB offset at pixel 01
  [15:0] WB_OFST00 — S16, WB offset at pixel 00
0x184 ded_enable_set_reg1 — Interrupt Enable Set Register 1
  [5] eelut_1_ramecc_enable_set — Interrupt Enable Set Register for eelut_1_ramecc_pend
  [4] eelut_0_ramecc_enable_set — Interrupt Enable Set Register for eelut_0_ramecc_pend
  [3] lut_1_ramecc_enable_set — Interrupt Enable Set Register for lut_1_ramecc_pend
  [2] lut_0_ramecc_enable_set — Interrupt Enable Set Register for lut_0_ramecc_pend
  [1] fcc_lut2_ram1_ramecc_enable_set — Interrupt Enable Set Register for fcc_lut2_ram1_ramecc_pend
  [0] fcc_lut2_ram0_ramecc_enable_set — Interrupt Enable Set Register for fcc_lut2_ram0_ramecc_pend
0x184 WB2_offset34 — WB2 white balance offset 3 and 4
  [31:16] WB_OFST11 — S16, WB offset at pixel 11
  [15:0] WB_OFST10 — S16, WB offset at pixel 10
0x188 WB2_gain12 access per field — WB2 white balance gain 1 and 2
  [28:16] WB_GAIN01 rw — U13Q9, WB gain at pixel 01
  [12:0] WB_GAIN00 rw — U13Q9, WB gain at pixel 00
0x18C WB2_gain34 access per field — WB2 white balance gain 3 and 4
  [28:16] WB_GAIN11 rw — U13Q9, WB gain at pixel 11
  [12:0] WB_GAIN10 rw — U13Q9, WB gain at pixel 10
0x190 H3AMUX_CFG access per field — H3A MUX configuration
  [5:2] SHIFT rw — U8, number of right shift, from 0 to 14
  [1:0] SEL rw — H3A input selection, 0: long frame, 1: short frame, 2: very short frame, 3: LSC output
0x194 H3ALUT_CFG access per field — H3A LUT configuration
  [25:16] CLIP rw — U10, LUT output clip value
  [5:1] BITS rw — U5, LUT input bit depth, up to 24
  [0] EN rw — LUT enable
0x198 RAWFE_INT_STAT — status/clear register for rawfe interrupts
  [9] LSC_CFG_ERR — status/clear for lsc config error. This is set when a write or read occurs in the middle of frame processing. This results in data corruption for the frame. write 1 to clear event status, write of 0 has no affect
  [8] DPC_LINE_CFG_ERR — status/clear for dpc line config error. This is set when a write or read occurs in the middle of frame processing. This results in data corruption for the frame. write 1 to clear event status, write of 0 has no affect
  [7] DPC_LUT_CFG_ERR — status/clear for dpc lut configuration error. This is set when a write or read occurs in the middle of frame processing. This results in data corruption for the frame. write 1 to clear event status, write of 0 has no affect
  [6] H3A_ACCM_CFG_ERR — status/clear for h3a accum configuration error. This is set when a write or read occurs in the middle of frame processing. This results in data corruption for the frame. write 1 to clear event status, write of 0 has no affect
  [5] H3A_LINE_CFG_ERR — status/clear for h3a line configuration error. This is set when a write or read occurs in the middle of frame processing. This results in data corruption for the frame. write 1 to clear event status, write of 0 has no affect
  [4] H3A_LUT_CFG_ERR — status/clear for h3a lut configuration error. This is set when a write or read occurs in the middle of frame processing. This results in data corruption for the frame. write 1 to clear event status, write of 0 has no affect
  [3] WDR_LUT_CFG_ERR — status/clear for wdr lut configuration error. This is set when a write or read occurs in the middle of frame processing. This results in data corruption for the frame. write 1 to clear event status, write of 0 has no affect
  [2] LUT3_CFG_ERR — status/clear for lut3 configuration error. This is set when a write or read occurs in the middle of frame processing. This results in data corruption for the frame. write 1 to clear event status, write of 0 has no affect
  [1] LUT2_CFG_ERR — status/clear for lut2 configuration error. This is set when a write or read occurs in the middle of frame processing. This results in data corruption for the frame. write 1 to clear event status, write of 0 has no affect
  [0] LUT1_CFG_ERR — status/clear for lut1 configuration error. This is set when a write or read occurs in the middle of frame processing. This results in data corruption for the frame. write 1 to clear event status, write of 0 has no affect
0x1A4 HWA1_prod6_control — Controlling producer socket6 for HWA1
  [26:24] mask_select — define which tdone_mask apply to prod socket 6. tdone_mask[mask_select] applies to prod_socket6
  [8:1] cons_select — consumer select for HWA1 prod socket 6. Used in decrementing count of producer buffer
  [0] prod_en — '1' -> Producer socket 0 enable , '0' Disable
0x1B8 HWA2_scheduler_control access per field — Scheduler Control Register
  [22] eor_en rw — '1' -> LDC REGION/sub-frame feature enabled, '0' LDC works in Frame mode only
  [12] debug_rdy rw — '0' -> HWA2 Scheduler resources must not be read during halted state. '1'-> HWA2 Scheduler resources are readable during halted state
  [10:7] state ro — Current state of HWA2 Scheduler
  [6] pause rw — '1' -> pause/suspend scheduler , '0' -> resume scheduler
  [5] strm_en rw — '1' -> Streaming input enable, '0' No streaming input
  [3:1] pipeline_num rw — Pipeline Number of HWA2 Scheduler
  [0] sch_en rw — scheduler enable; write '1' to enable scheduler
{0x44+0xBC*i} HWA{i}_HOP (i=2..4) — Scheduler HOP Control Register. Help in detecting eop within scheduler. Once configured, it counts task/channel starts and stops issuing further starts. Specifically useful for Head of pipe dma scheduler .
  fields as HWA1_HOP
{0x1C0+0x20*i} enable_reg_pulse_vpac_out_{i}_0 (i=0..5) — Enable Register {8i+48}
  [24] enable_pulse_vpac_out_{i}_en_viss0_lse_out_fr_start_evt — Enable Set for pulse_vpac_out_{i}_en_viss0_lse_out_fr_start_evt
  [23] enable_pulse_vpac_out_{i}_en_viss0_lse_cal_vp_err — Enable Set for pulse_vpac_out_{i}_en_viss0_lse_cal_vp_err
  [22] enable_pulse_vpac_out_{i}_en_viss0_lse_sl2_wr_err — Enable Set for pulse_vpac_out_{i}_en_viss0_lse_sl2_wr_err
  [21] enable_pulse_vpac_out_{i}_en_viss0_lse_sl2_rd_err — Enable Set for pulse_vpac_out_{i}_en_viss0_lse_sl2_rd_err
  [20] enable_pulse_vpac_out_{i}_en_viss0_lse_fr_done_evt — Enable Set for pulse_vpac_out_{i}_en_viss0_lse_fr_done_evt
  [19] enable_pulse_vpac_out_{i}_en_viss0_ee_syncovf_err — Enable Set for pulse_vpac_out_{i}_en_viss0_ee_syncovf_err
  [18] enable_pulse_vpac_out_{i}_en_viss0_ee_cfg_err — Enable Set for pulse_vpac_out_{i}_en_viss0_ee_cfg_err
  [17] enable_pulse_vpac_out_{i}_en_viss0_fcc_hist_read_err — Enable Set for pulse_vpac_out_{i}_en_viss0_fcc_hist_read_err
  [16] enable_pulse_vpac_out_{i}_en_viss0_fcc_outif_ovf_err — Enable Set for pulse_vpac_out_{i}_en_viss0_fcc_outif_ovf_err
  [15] enable_pulse_vpac_out_{i}_en_viss0_fcc_cfg_err — Enable Set for pulse_vpac_out_{i}_en_viss0_fcc_cfg_err
  [14] enable_pulse_vpac_out_{i}_en_viss0_fcfa_cfg_err — Enable Set for pulse_vpac_out_{i}_en_viss0_fcfa_cfg_err
  [13] enable_pulse_vpac_out_{i}_en_viss0_glbce_vp_err — Enable Set for pulse_vpac_out_{i}_en_viss0_glbce_vp_err
  [12] enable_pulse_vpac_out_{i}_en_viss0_glbce_vsync_err — Enable Set for pulse_vpac_out_{i}_en_viss0_glbce_vsync_err
  [11] enable_pulse_vpac_out_{i}_en_viss0_glbce_hsync_err — Enable Set for pulse_vpac_out_{i}_en_viss0_glbce_hsync_err
  [10] enable_pulse_vpac_out_{i}_en_viss0_glbce_filt_done — Enable Set for pulse_vpac_out_{i}_en_viss0_glbce_filt_done
  [9] enable_pulse_vpac_out_{i}_en_viss0_glbce_filt_start — Enable Set for pulse_vpac_out_{i}_en_viss0_glbce_filt_start
  [8] enable_pulse_vpac_out_{i}_en_viss0_glbce_cfg_err — Enable Set for pulse_vpac_out_{i}_en_viss0_glbce_cfg_err
  [7] enable_pulse_vpac_out_{i}_en_viss0_nsf4v_vblank_err — Enable Set for pulse_vpac_out_{i}_en_viss0_nsf4v_vblank_err
  [6] enable_pulse_vpac_out_{i}_en_viss0_nsf4v_hblank_err — Enable Set for pulse_vpac_out_{i}_en_viss0_nsf4v_hblank_err
  [5] enable_pulse_vpac_out_{i}_en_viss0_nsf4v_linemem_cfg_err — Enable Set for pulse_vpac_out_{i}_en_viss0_nsf4v_linemem_cfg_err
  [4] enable_pulse_vpac_out_{i}_en_viss0_rawfe_h3a_buf_ovrflow_pulse — Enable Set for pulse_vpac_out_{i}_en_viss0_rawfe_h3a_buf_ovrflow_pulse
  [3] enable_pulse_vpac_out_{i}_en_viss0_rawfe_h3a_pulse — Enable Set for pulse_vpac_out_{i}_en_viss0_rawfe_h3a_pulse
  [2] enable_pulse_vpac_out_{i}_en_viss0_rawfe_af_pulse — Enable Set for pulse_vpac_out_{i}_en_viss0_rawfe_af_pulse
  [1] enable_pulse_vpac_out_{i}_en_viss0_rawfe_aew_pulse — Enable Set for pulse_vpac_out_{i}_en_viss0_rawfe_aew_pulse
  [0] enable_pulse_vpac_out_{i}_en_viss0_rawfe_cfg_err — Enable Set for pulse_vpac_out_{i}_en_viss0_rawfe_cfg_err
0x1C0 ded_enable_clr_reg0 — Interrupt Enable Clear Register 0
  [13] utc1_dru_state_buffer0_ecc_enable_clr — Interrupt Enable Clear Register for utc1_dru_state_buffer0_ecc_pend
  [12] utc1_dru_queue_buffer2_ecc_enable_clr — Interrupt Enable Clear Register for utc1_dru_queue_buffer2_ecc_pend
  [11] utc1_dru_queue_buffer1_ecc_enable_clr — Interrupt Enable Clear Register for utc1_dru_queue_buffer1_ecc_pend
  [10] utc1_dru_queue_buffer0_ecc_enable_clr — Interrupt Enable Clear Register for utc1_dru_queue_buffer0_ecc_pend
  [9] utc1_tpram_dru_response_buffer0_ecc_enable_clr — Interrupt Enable Clear Register for utc1_tpram_dru_response_buffer0_ecc_pend
  [8] utc1_dru_psi_edc_enable_clr — Interrupt Enable Clear Register for utc1_dru_psi_edc_pend
  [7] utc1_dru_eng_edc_enable_clr — Interrupt Enable Clear Register for utc1_dru_eng_edc_pend
  [6] utc0_dru_state_buffer0_ecc_enable_clr — Interrupt Enable Clear Register for utc0_dru_state_buffer0_ecc_pend
  [5] utc0_dru_queue_buffer2_ecc_enable_clr — Interrupt Enable Clear Register for utc0_dru_queue_buffer2_ecc_pend
  [4] utc0_dru_queue_buffer1_ecc_enable_clr — Interrupt Enable Clear Register for utc0_dru_queue_buffer1_ecc_pend
  [3] utc0_dru_queue_buffer0_ecc_enable_clr — Interrupt Enable Clear Register for utc0_dru_queue_buffer0_ecc_pend
  [2] utc0_tpram_dru_response_buffer0_ecc_enable_clr — Interrupt Enable Clear Register for utc0_tpram_dru_response_buffer0_ecc_pend
  [1] utc0_dru_psi_edc_enable_clr — Interrupt Enable Clear Register for utc0_dru_psi_edc_pend
  [0] utc0_dru_eng_edc_enable_clr — Interrupt Enable Clear Register for utc0_dru_eng_edc_pend
0x1C0 ded_enable_clr_reg0 — Interrupt Enable Clear Register 0
  [n+8] meshmem_b{n}_p1_ramecc_enable_clr (n=0..3) — Interrupt Enable Clear Register for meshmem_b{n}_p1_ramecc_pend
  [n+4] meshmem_b{n}_p0_ramecc_enable_clr (n=0..3) — Interrupt Enable Clear Register for meshmem_b{n}_p0_ramecc_pend
  [3] dualc_lut_b1_ramecc_enable_clr — Interrupt Enable Clear Register for dualc_lut_b1_ramecc_pend
  [2] dualc_lut_b0_ramecc_enable_clr — Interrupt Enable Clear Register for dualc_lut_b0_ramecc_pend
  [1] dualy_lut_b1_ramecc_enable_clr — Interrupt Enable Clear Register for dualy_lut_b1_ramecc_pend
  [0] dualy_lut_b0_ramecc_enable_clr — Interrupt Enable Clear Register for dualy_lut_b0_ramecc_pend
0x1C0 ded_enable_clr_reg0 — Interrupt Enable Clear Register 0
  [31] fcc_lut1_ram1_ramecc_enable_clr — Interrupt Enable Clear Register for fcc_lut1_ram1_ramecc_pend
  [30] fcc_lut1_ram0_ramecc_enable_clr — Interrupt Enable Clear Register for fcc_lut1_ram0_ramecc_pend
  [29] fcc_lut0_ram1_ramecc_enable_clr — Interrupt Enable Clear Register for fcc_lut0_ram1_ramecc_pend
  [28] fcc_lut0_ram0_ramecc_enable_clr — Interrupt Enable Clear Register for fcc_lut0_ram0_ramecc_pend
  [27] fcc_cont_lut3_ram1_ramecc_enable_clr — Interrupt Enable Clear Register for fcc_cont_lut3_ram1_ramecc_pend
  [26] fcc_cont_lut3_ram0_ramecc_enable_clr — Interrupt Enable Clear Register for fcc_cont_lut3_ram0_ramecc_pend
  [25] fcc_cont_lut2_ram1_ramecc_enable_clr — Interrupt Enable Clear Register for fcc_cont_lut2_ram1_ramecc_pend
  [24] fcc_cont_lut2_ram0_ramecc_enable_clr — Interrupt Enable Clear Register for fcc_cont_lut2_ram0_ramecc_pend
  [23] fcc_cont_lut1_ram1_ramecc_enable_clr — Interrupt Enable Clear Register for fcc_cont_lut1_ram1_ramecc_pend
  [22] fcc_cont_lut1_ram0_ramecc_enable_clr — Interrupt Enable Clear Register for fcc_cont_lut1_ram0_ramecc_pend
  [21] fcc_hist_ram1_ramecc_enable_clr — Interrupt Enable Clear Register for fcc_hist_ram1_ramecc_pend
  [20] fcc_hist_ram0_ramecc_enable_clr — Interrupt Enable Clear Register for fcc_hist_ram0_ramecc_pend
  [n+12] stat_mem{n}_ramecc_enable_clr (n=0..7) — Interrupt Enable Clear Register for stat_mem{n}_ramecc_pend
  [11] h3a_lut_ram1_ramecc_enable_clr — Interrupt Enable Clear Register for h3a_lut_ram1_ramecc_pend
  [10] h3a_lut_ram0_ramecc_enable_clr — Interrupt Enable Clear Register for h3a_lut_ram0_ramecc_pend
  [9] lsc_ramecc_enable_clr — Interrupt Enable Clear Register for lsc_ramecc_pend
  [8] dpc_lut_ramecc_enable_clr — Interrupt Enable Clear Register for dpc_lut_ramecc_pend
  [7] wdr_lut_ram1_ramecc_enable_clr — Interrupt Enable Clear Register for wdr_lut_ram1_ramecc_pend
  [6] wdr_lut_ram0_ramecc_enable_clr — Interrupt Enable Clear Register for wdr_lut_ram0_ramecc_pend
  [5] lut1_ram1_ramecc_enable_clr — Interrupt Enable Clear Register for lut1_ram1_ramecc_pend
  [4] lut1_ram0_ramecc_enable_clr — Interrupt Enable Clear Register for lut1_ram0_ramecc_pend
  [3] lut2_ram1_ramecc_enable_clr — Interrupt Enable Clear Register for lut2_ram1_ramecc_pend
  [2] lut2_ram0_ramecc_enable_clr — Interrupt Enable Clear Register for lut2_ram0_ramecc_pend
  [1] lut3_ram1_ramecc_enable_clr — Interrupt Enable Clear Register for lut3_ram1_ramecc_pend
  [0] lut3_ram0_ramecc_enable_clr — Interrupt Enable Clear Register for lut3_ram0_ramecc_pend
{0x1C4+0x20*i} enable_reg_pulse_vpac_out_{i}_1 (i=0..5) — Enable Register {8i+49}
  [8] enable_pulse_vpac_out_{i}_en_ldc0_vbusm_rd_err — Enable Set for pulse_vpac_out_{i}_en_ldc0_vbusm_rd_err
  [7] enable_pulse_vpac_out_{i}_en_ldc0_sl2_wr_err — Enable Set for pulse_vpac_out_{i}_en_ldc0_sl2_wr_err
  [6] enable_pulse_vpac_out_{i}_en_ldc0_fr_done_evt — Enable Set for pulse_vpac_out_{i}_en_ldc0_fr_done_evt
  [5] enable_pulse_vpac_out_{i}_en_ldc0_int_szovf — Enable Set for pulse_vpac_out_{i}_en_ldc0_int_szovf
  [4] enable_pulse_vpac_out_{i}_en_ldc0_ifr_outofbound — Enable Set for pulse_vpac_out_{i}_en_ldc0_ifr_outofbound
  [3] enable_pulse_vpac_out_{i}_en_ldc0_mesh_iblk_memovf — Enable Set for pulse_vpac_out_{i}_en_ldc0_mesh_iblk_memovf
  [2] enable_pulse_vpac_out_{i}_en_ldc0_pix_iblk_memovf — Enable Set for pulse_vpac_out_{i}_en_ldc0_pix_iblk_memovf
  [1] enable_pulse_vpac_out_{i}_en_ldc0_mesh_iblk_outofbound — Enable Set for pulse_vpac_out_{i}_en_ldc0_mesh_iblk_outofbound
  [0] enable_pulse_vpac_out_{i}_en_ldc0_pix_iblk_outofbound — Enable Set for pulse_vpac_out_{i}_en_ldc0_pix_iblk_outofbound
0x1C4 ded_enable_clr_reg1 — Interrupt Enable Clear Register 1
  [5] eelut_1_ramecc_enable_clr — Interrupt Enable Clear Register for eelut_1_ramecc_pend
  [4] eelut_0_ramecc_enable_clr — Interrupt Enable Clear Register for eelut_0_ramecc_pend
  [3] lut_1_ramecc_enable_clr — Interrupt Enable Clear Register for lut_1_ramecc_pend
  [2] lut_0_ramecc_enable_clr — Interrupt Enable Clear Register for lut_0_ramecc_pend
  [1] fcc_lut2_ram1_ramecc_enable_clr — Interrupt Enable Clear Register for fcc_lut2_ram1_ramecc_pend
  [0] fcc_lut2_ram0_ramecc_enable_clr — Interrupt Enable Clear Register for fcc_lut2_ram0_ramecc_pend
{0x1C8+0x20*i} enable_reg_pulse_vpac_out_{i}_2 (i=0..5) — Enable Register {8i+50}
  [10] enable_pulse_vpac_out_{i}_en_nf_sl2_rd_err — Enable Set for pulse_vpac_out_{i}_en_nf_sl2_rd_err
  [9] enable_pulse_vpac_out_{i}_en_nf_sl2_wr_err — Enable Set for pulse_vpac_out_{i}_en_nf_sl2_wr_err
  [8] enable_pulse_vpac_out_{i}_en_nf_frame_done — Enable Set for pulse_vpac_out_{i}_en_nf_frame_done
  [3] enable_pulse_vpac_out_{i}_en_msc_lse_sl2_wr_err — Enable Set for pulse_vpac_out_{i}_en_msc_lse_sl2_wr_err
  [2] enable_pulse_vpac_out_{i}_en_msc_lse_sl2_rd_err — Enable Set for pulse_vpac_out_{i}_en_msc_lse_sl2_rd_err
  [1] enable_pulse_vpac_out_{i}_en_msc_lse_fr_done_evt_1 — Enable Set for pulse_vpac_out_{i}_en_msc_lse_fr_done_evt_1
  [0] enable_pulse_vpac_out_{i}_en_msc_lse_fr_done_evt_0 — Enable Set for pulse_vpac_out_{i}_en_msc_lse_fr_done_evt_0
{0x1C8+4i} HWA2_cons{i}_control (i=0..2) — Controlling consumer socket {i} for HWA2
  [9:1] prod_select — producer select for HWA2 cons socket {i}
  [0] cons_en — '1' -> Consumer socket {i} enable , '0' Disable
{0x1CC+0x20*i} enable_reg_pulse_vpac_out_{i}_3 (i=0..5) — Enable Register {8i+51}
  [26] enable_pulse_vpac_out_{i}_en_watchdogtimer_err_6 — Enable Set for pulse_vpac_out_{i}_en_watchdogtimer_err_6
  [25] enable_pulse_vpac_out_{i}_en_watchdogtimer_err_5 — Enable Set for pulse_vpac_out_{i}_en_watchdogtimer_err_5
  [24] enable_pulse_vpac_out_{i}_en_watchdogtimer_err_4 — Enable Set for pulse_vpac_out_{i}_en_watchdogtimer_err_4
  [22] enable_pulse_vpac_out_{i}_en_watchdogtimer_err_2 — Enable Set for pulse_vpac_out_{i}_en_watchdogtimer_err_2
  [20] enable_pulse_vpac_out_{i}_en_watchdogtimer_err_0 — Enable Set for pulse_vpac_out_{i}_en_watchdogtimer_err_0
  [19] enable_pulse_vpac_out_{i}_en_spare_pend_1_level — Enable Set for pulse_vpac_out_{i}_en_spare_pend_1_level
  [18] enable_pulse_vpac_out_{i}_en_spare_pend_1_pulse — Enable Set for pulse_vpac_out_{i}_en_spare_pend_1_pulse
  [17] enable_pulse_vpac_out_{i}_en_spare_pend_0_level — Enable Set for pulse_vpac_out_{i}_en_spare_pend_0_level
  [16] enable_pulse_vpac_out_{i}_en_spare_pend_0_pulse — Enable Set for pulse_vpac_out_{i}_en_spare_pend_0_pulse
  [15] enable_pulse_vpac_out_{i}_en_spare_dec_1 — Enable Set for pulse_vpac_out_{i}_en_spare_dec_1
  [14] enable_pulse_vpac_out_{i}_en_spare_dec_0 — Enable Set for pulse_vpac_out_{i}_en_spare_dec_0
  [13] enable_pulse_vpac_out_{i}_en_tdone_6 — Enable Set for pulse_vpac_out_{i}_en_tdone_6
  [12] enable_pulse_vpac_out_{i}_en_tdone_5 — Enable Set for pulse_vpac_out_{i}_en_tdone_5
  [11] enable_pulse_vpac_out_{i}_en_tdone_4 — Enable Set for pulse_vpac_out_{i}_en_tdone_4
  [9] enable_pulse_vpac_out_{i}_en_tdone_2 — Enable Set for pulse_vpac_out_{i}_en_tdone_2
  [7] enable_pulse_vpac_out_{i}_en_tdone_0 — Enable Set for pulse_vpac_out_{i}_en_tdone_0
  [n] enable_pulse_vpac_out_{i}_en_pipe_done_{n} (n=0..6) — Enable Set for pulse_vpac_out_{i}_en_pipe_done_{n}
